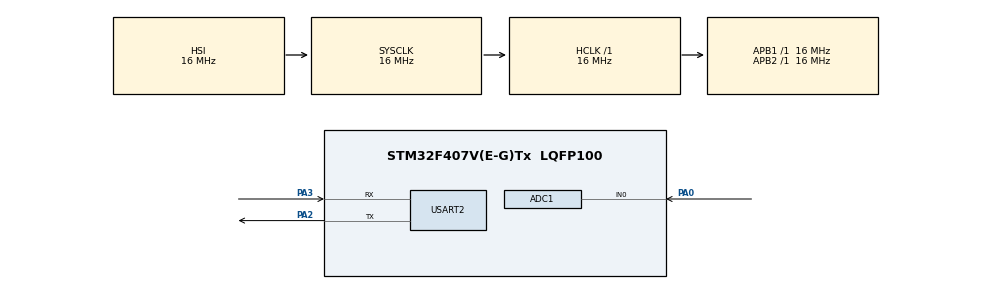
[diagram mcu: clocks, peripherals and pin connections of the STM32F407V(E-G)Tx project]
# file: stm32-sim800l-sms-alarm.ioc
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ADC1.Channel-0\#ChannelRegularConversion=ADC_CHANNEL_0
ADC1.ContinuousConvMode=ENABLE
ADC1.DMAContinuousRequests=ENABLE
ADC1.NbrOfConversion=1
ADC1.NbrOfConversionFlag=1
ADC1.Rank-0\#ChannelRegularConversion=1
ADC1.SamplingTime-0\#ChannelRegularConversion=ADC_SAMPLETIME_480CYCLES
ADC1.ScanConvMode=ENABLE
ADC1.master=1
Dma.ADC1.0.Direction=DMA_PERIPH_TO_MEMORY
Dma.ADC1.0.FIFOMode=DMA_FIFOMODE_DISABLE
Dma.ADC1.0.Instance=DMA2_Stream0
Dma.ADC1.0.MemDataAlignment=DMA_MDATAALIGN_WORD
Dma.ADC1.0.MemInc=DMA_MINC_ENABLE
Dma.ADC1.0.Mode=DMA_CIRCULAR
Dma.ADC1.0.PeriphDataAlignment=DMA_PDATAALIGN_WORD
Dma.ADC1.0.PeriphInc=DMA_PINC_DISABLE
Dma.ADC1.0.Priority=DMA_PRIORITY_LOW
Dma.Request0=ADC1
Mcu.Family=STM32F4
Mcu.Name=STM32F407V(E-G)Tx
Mcu.Package=LQFP100
NVIC.DMA2_Stream0_IRQn=true\:0\:0\:false\:false\:true\:false\:true\:true
NVIC.PriorityGroup=NVIC_PRIORITYGROUP_4
PA0-WKUP.Signal=ADCx_IN0
PA2.Mode=Asynchronous
PA2.Signal=USART2_TX
PA3.Mode=Asynchronous
PA3.Signal=USART2_RX
ProjectManager.HeapSize=0x200
ProjectManager.StackSize=0x400
ProjectManager.TargetToolchain=STM32CubeIDE
RCC.AHBFreq_Value=16000000
RCC.APB1Freq_Value=16000000
RCC.APB2Freq_Value=16000000
RCC.CortexFreq_Value=16000000
RCC.HSE_VALUE=25000000
RCC.HSI_VALUE=16000000
RCC.LSE_VALUE=32768
RCC.SYSCLKFreq_VALUE=16000000
RCC.VCOOutputFreq_Value=192000000
SH.ADCx_IN0.0=ADC1_IN0,IN0
USART2.VirtualMode=VM_ASYNC
board=custom

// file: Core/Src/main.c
/* USER CODE BEGIN Header */
/**
  ******************************************************************************
  * @file           : main.c
  * @brief          : Main program body
  * @author         : M. Eyub Can, TECH-OHM (https://tech-ohm.com)
  ******************************************************************************
  * @attention
  *
  * Copyright (c) 2025 STMicroelectronics.
  * All rights reserved.
  *
  * This software is licensed under terms that can be found in the LICENSE file
  * in the root directory of this software component.
  * If no LICENSE file comes with this software, it is provided AS-IS.
  *
  ******************************************************************************
  */
/* USER CODE END Header */
#include "main.h"

/* USER CODE BEGIN Includes */
#include <string.h>
#include <stdio.h>

uint32_t pot1;

char sms_mesaji[100];              // buffer for the SMS command
uint8_t sms_gonderildi = 0;        // set once an SMS has gone out, so it is not sent again and again

char sim800_rx_buffer[200];   // UART RX buffer
char gelen_sms[160];          // message text with the header lines stripped

/* USER CODE END Includes */

ADC_HandleTypeDef hadc1;
DMA_HandleTypeDef hdma_adc1;

UART_HandleTypeDef huart2;

void SystemClock_Config(void);
static void MX_GPIO_Init(void);
static void MX_DMA_Init(void);
static void MX_ADC1_Init(void);
static void MX_USART2_UART_Init(void);
/* USER CODE BEGIN PFP */

void SIM800_Send_AT(char *komut, uint16_t bekleme_ms) {
    char crlf[] = "\r\n";
    HAL_UART_Transmit(&huart2, (uint8_t*)komut, strlen(komut), HAL_MAX_DELAY);
    HAL_UART_Transmit(&huart2, (uint8_t*)crlf, 2, HAL_MAX_DELAY);
    HAL_Delay(bekleme_ms);
}

void SIM800_Send_SMS(char *numara, char *mesaj) {
    SIM800_Send_AT("AT", 500);               // start with a plain AT
    SIM800_Send_AT("AT+CMGF=1", 500);        // text mode

    sprintf(sms_mesaji, "AT+CMGS=\"%s\"", numara);
    SIM800_Send_AT(sms_mesaji, 500);

    HAL_UART_Transmit(&huart2, (uint8_t*)mesaj, strlen(mesaj), HAL_MAX_DELAY);

    uint8_t ctrl_z = 26;  // Ctrl+Z
    HAL_UART_Transmit(&huart2, &ctrl_z, 1, HAL_MAX_DELAY);

    HAL_Delay(5000); // give the module time to send

}

void SIM800_Read_SMS(void) {
    SIM800_Send_AT("AT+CMGF=1", 500);
    SIM800_Send_AT("AT+CPMS=\"SM\"", 500);
    SIM800_Send_AT("AT+CMGL=\"REC UNREAD\"", 1000);  // list unread messages

    // Read what the module sent back
    memset(sim800_rx_buffer, 0, sizeof(sim800_rx_buffer));
    HAL_UART_Receive(&huart2, (uint8_t*)sim800_rx_buffer, sizeof(sim800_rx_buffer), 2000);

    // Pull the message text out of the reply
    char *msg_start = strstr(sim800_rx_buffer, "\n");  // skip to the first newline
    if (msg_start != NULL) {
        msg_start = strstr(msg_start + 1, "\n");  // second newline, where the message starts
        if (msg_start != NULL) {
            msg_start++;  // step past the "\n"
            strncpy(gelen_sms, msg_start, 159);
            gelen_sms[159] = '\0';  // null-terminate
        }
    }
}

/* USER CODE END PFP */

int main(void)
{

  /* MCU Configuration--------------------------------------------------------*/

  /* Reset of all peripherals, Initializes the Flash interface and the Systick. */
  HAL_Init();

  /* Configure the system clock */
  SystemClock_Config();

  /* Initialize all configured peripherals */
  MX_GPIO_Init();
  MX_DMA_Init();
  MX_ADC1_Init();
  MX_USART2_UART_Init();
  /* USER CODE BEGIN 2 */
  HAL_ADC_Start_DMA(&hadc1,&pot1,1);
  /* USER CODE END 2 */

  /* Infinite loop */
  while (1)
  {

    /* USER CODE BEGIN 3 */
	  	  if (pot1 > 3000 && sms_gonderildi == 0)
	  	  {
	          SIM800_Send_SMS("05XXXXXXXXX", "WARNING: value is above 3000!");
	          sms_gonderildi = 1;  // send once, do not repeat
	      }

	      // Re-arm when the value drops below 2800
	      if (pot1 < 2800) {
	          sms_gonderildi = 0;
	      }

	      HAL_Delay(1000);  // check once a second

  }
  /* USER CODE END 3 */
}

void SystemClock_Config(void)
{
  RCC_OscInitTypeDef RCC_OscInitStruct = {0};
  RCC_ClkInitTypeDef RCC_ClkInitStruct = {0};

  /** Configure the main internal regulator output voltage
  */
  __HAL_RCC_PWR_CLK_ENABLE();
  __HAL_PWR_VOLTAGESCALING_CONFIG(PWR_REGULATOR_VOLTAGE_SCALE1);

  /** Initializes the RCC Oscillators according to the specified parameters
  * in the RCC_OscInitTypeDef structure.
  */
  RCC_OscInitStruct.OscillatorType = RCC_OSCILLATORTYPE_HSI;
  RCC_OscInitStruct.HSIState = RCC_HSI_ON;
  RCC_OscInitStruct.HSICalibrationValue = RCC_HSICALIBRATION_DEFAULT;
  RCC_OscInitStruct.PLL.PLLState = RCC_PLL_NONE;
  if (HAL_RCC_OscConfig(&RCC_OscInitStruct) != HAL_OK)
  {
    Error_Handler();
  }

  /** Initializes the CPU, AHB and APB buses clocks
  */
  RCC_ClkInitStruct.ClockType = RCC_CLOCKTYPE_HCLK|RCC_CLOCKTYPE_SYSCLK
                              |RCC_CLOCKTYPE_PCLK1|RCC_CLOCKTYPE_PCLK2;
  RCC_ClkInitStruct.SYSCLKSource = RCC_SYSCLKSOURCE_HSI;
  RCC_ClkInitStruct.AHBCLKDivider = RCC_SYSCLK_DIV1;
  RCC_ClkInitStruct.APB1CLKDivider = RCC_HCLK_DIV1;
  RCC_ClkInitStruct.APB2CLKDivider = RCC_HCLK_DIV1;

  if (HAL_RCC_ClockConfig(&RCC_ClkInitStruct, FLASH_LATENCY_0) != HAL_OK)
  {
    Error_Handler();
  }
}

static void MX_ADC1_Init(void)
{

  ADC_ChannelConfTypeDef sConfig = {0};

  /** Configure the global features of the ADC (Clock, Resolution, Data Alignment and number of conversion)
  */
  hadc1.Instance = ADC1;
  hadc1.Init.ClockPrescaler = ADC_CLOCK_SYNC_PCLK_DIV2;
  hadc1.Init.Resolution = ADC_RESOLUTION_12B;
  hadc1.Init.ScanConvMode = ENABLE;
  hadc1.Init.ContinuousConvMode = ENABLE;
  hadc1.Init.DiscontinuousConvMode = DISABLE;
  hadc1.Init.ExternalTrigConvEdge = ADC_EXTERNALTRIGCONVEDGE_NONE;
  hadc1.Init.ExternalTrigConv = ADC_SOFTWARE_START;
  hadc1.Init.DataAlign = ADC_DATAALIGN_RIGHT;
  hadc1.Init.NbrOfConversion = 1;
  hadc1.Init.DMAContinuousRequests = ENABLE;
  hadc1.Init.EOCSelection = ADC_EOC_SINGLE_CONV;
  if (HAL_ADC_Init(&hadc1) != HAL_OK)
  {
    Error_Handler();
  }

  /** Configure for the selected ADC regular channel its corresponding rank in the sequencer and its sample time.
  */
  sConfig.Channel = ADC_CHANNEL_0;
  sConfig.Rank = 1;
  sConfig.SamplingTime = ADC_SAMPLETIME_480CYCLES;
  if (HAL_ADC_ConfigChannel(&hadc1, &sConfig) != HAL_OK)
  {
    Error_Handler();
  }

}

static void MX_USART2_UART_Init(void)
{

  huart2.Instance = USART2;
  huart2.Init.BaudRate = 115200;
  huart2.Init.WordLength = UART_WORDLENGTH_8B;
  huart2.Init.StopBits = UART_STOPBITS_1;
  huart2.Init.Parity = UART_PARITY_NONE;
  huart2.Init.Mode = UART_MODE_TX_RX;
  huart2.Init.HwFlowCtl = UART_HWCONTROL_NONE;
  huart2.Init.OverSampling = UART_OVERSAMPLING_16;
  if (HAL_UART_Init(&huart2) != HAL_OK)
  {
    Error_Handler();
  }

}

static void MX_DMA_Init(void)
{

  /* DMA controller clock enable */
  __HAL_RCC_DMA2_CLK_ENABLE();

  /* DMA interrupt init */
  /* DMA2_Stream0_IRQn interrupt configuration */
  HAL_NVIC_SetPriority(DMA2_Stream0_IRQn, 0, 0);
  HAL_NVIC_EnableIRQ(DMA2_Stream0_IRQn);

}

static void MX_GPIO_Init(void)
{

  /* GPIO Ports Clock Enable */
  __HAL_RCC_GPIOA_CLK_ENABLE();

}

void Error_Handler(void)
{
  __disable_irq();
  while (1)
  {
  }
}
